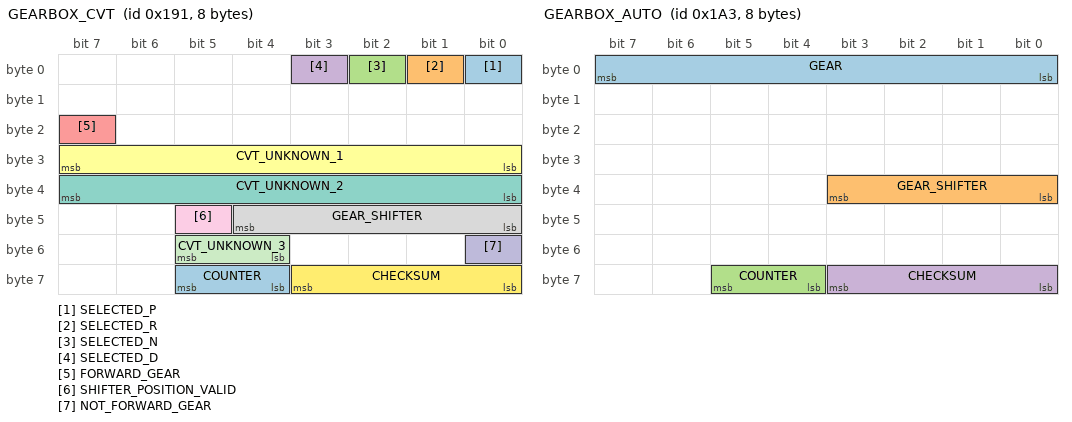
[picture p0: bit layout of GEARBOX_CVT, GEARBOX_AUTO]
BO_ 401 GEARBOX_CVT: 8 PCM
 SG_ SELECTED_P : 0|1@0+ (1,0) [0|1] "" XXX
 SG_ SELECTED_R : 1|1@0+ (1,0) [0|1] "" XXX
 SG_ SELECTED_N : 2|1@0+ (1,0) [0|1] "" XXX
 SG_ SELECTED_D : 3|1@0+ (1,0) [0|1] "" XXX
 SG_ FORWARD_GEAR : 23|1@0+ (1,0) [0|1] "" XXX
 SG_ CVT_UNKNOWN_1 : 31|8@0+ (1,0) [0|255] "" XXX
 SG_ CVT_UNKNOWN_2 : 39|8@0+ (1,0) [0|255] "" XXX
 SG_ GEAR_SHIFTER : 44|5@0+ (1,0) [0|31] "" XXX
 SG_ SHIFTER_POSITION_VALID : 45|1@0+ (1,0) [0|1] "" XXX
 SG_ NOT_FORWARD_GEAR : 48|1@0+ (1,0) [0|1] "" XXX
 SG_ CVT_UNKNOWN_3 : 53|2@0+ (1,0) [0|3] "" XXX
 SG_ CHECKSUM : 59|4@0+ (1,0) [0|15] "" EON
 SG_ COUNTER : 61|2@0+ (1,0) [0|3] "" EON

BO_ 419 GEARBOX_AUTO: 8 PCM
 SG_ GEAR : 7|8@0+ (1,0) [0|256] "" EON
 SG_ GEAR_SHIFTER : 35|4@0+ (1,0) [0|15] "" EON
 SG_ COUNTER : 61|2@0+ (1,0) [0|3] "" EON
 SG_ CHECKSUM : 59|4@0+ (1,0) [0|3] "" EON

CM_ SG_ 401 CVT_UNKNOWN_1 "Probably measured/actual CVT ratio";
CM_ SG_ 401 CVT_UNKNOWN_2 "Probably target/commanded CVT ratio";

VAL_ 401 GEAR_SHIFTER 1 "P" 2 "R" 3 "N" 4 "D" 7 "L" 10 "S";
VAL_ 419 GEAR_SHIFTER 1 "P" 2 "R" 3 "N" 4 "D" 7 "L" 10 "S";
